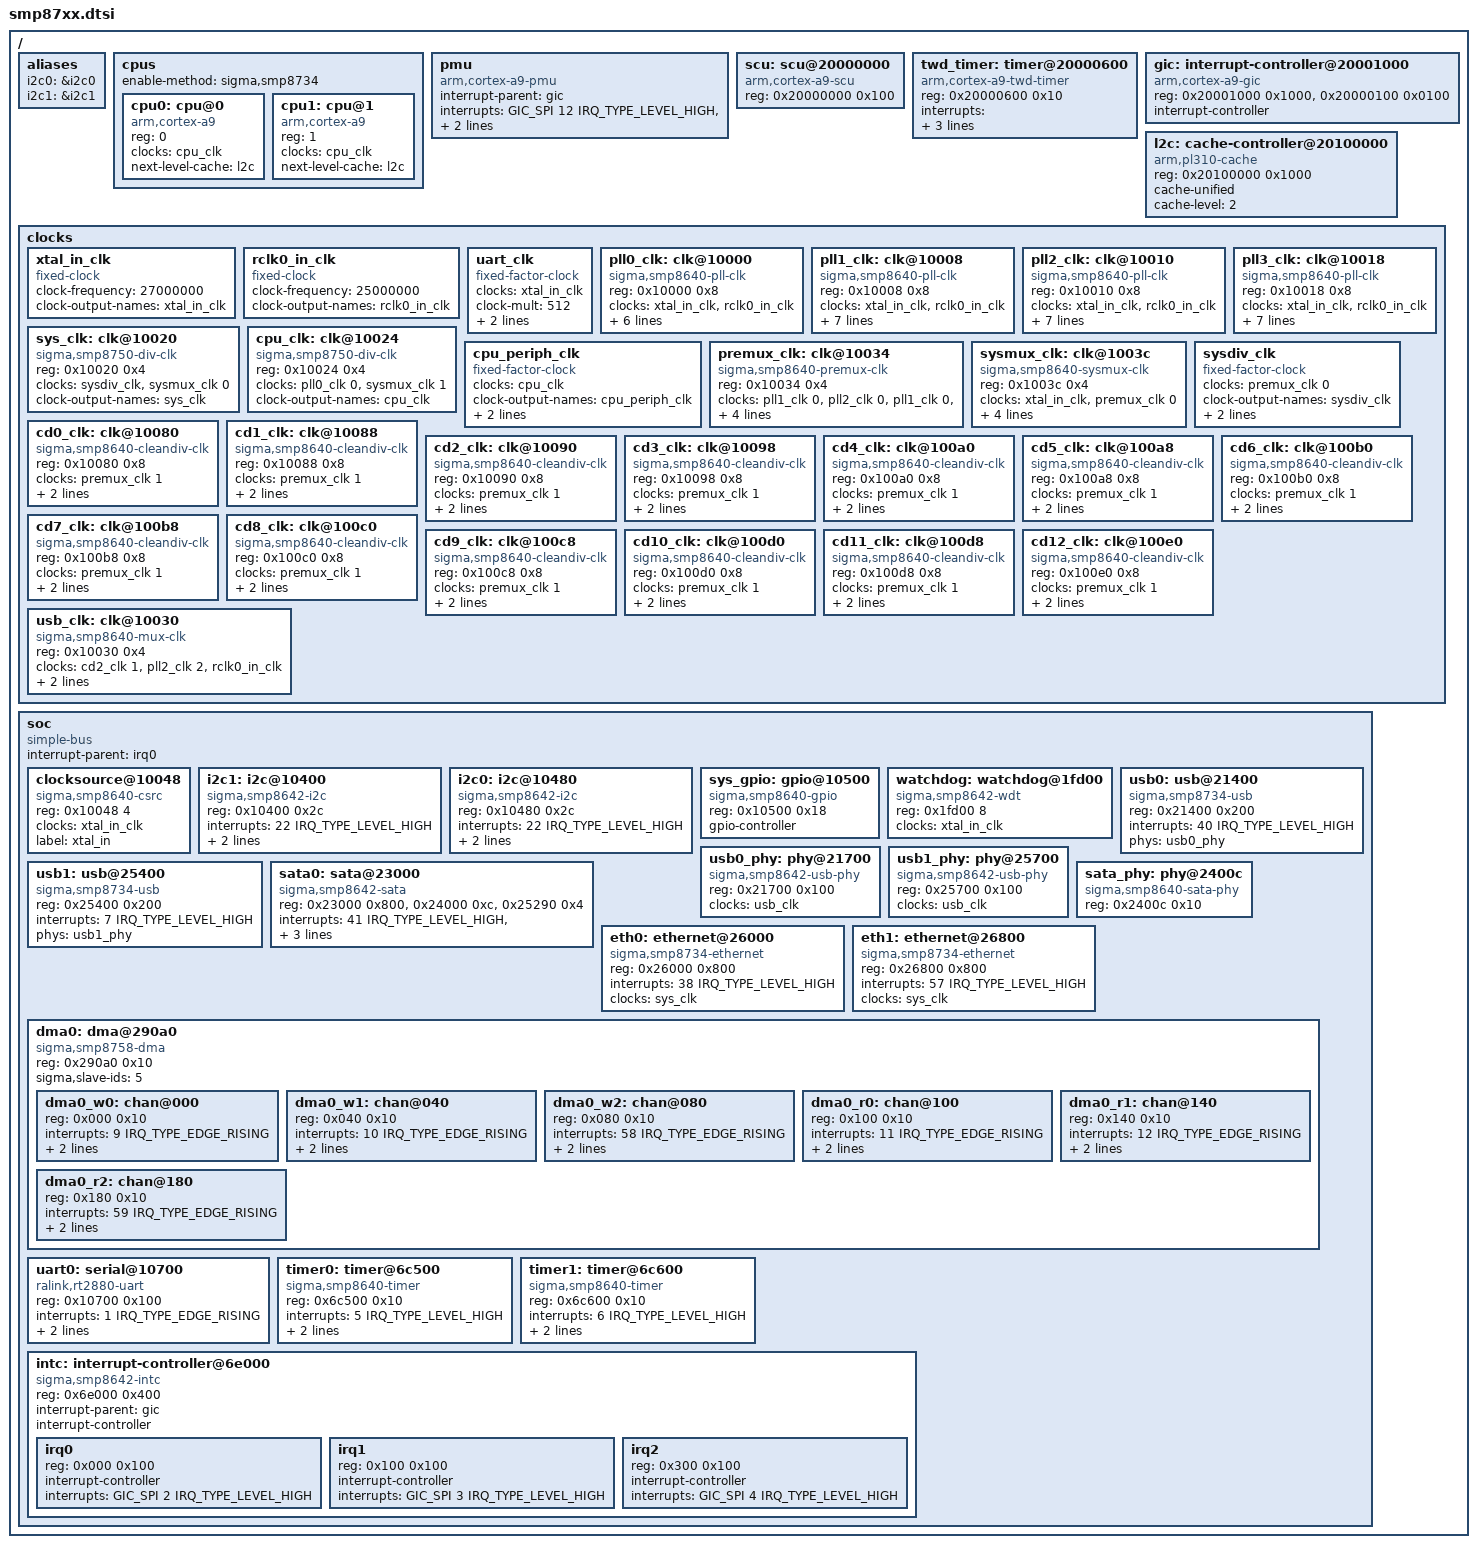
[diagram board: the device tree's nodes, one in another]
#include <dt-bindings/interrupt-controller/irq.h>
#include <dt-bindings/interrupt-controller/arm-gic.h>

/ {
	#address-cells = <1>;
	#size-cells = <1>;

	aliases {
		i2c0 = &i2c0;
		i2c1 = &i2c1;
	};

	cpus {
		enable-method = "sigma,smp8734";
		#address-cells = <1>;
		#size-cells = <0>;

		cpu0: cpu@0 {
			compatible = "arm,cortex-a9";
			device_type = "cpu";
			reg = <0>;
			clocks = <&cpu_clk>;
			next-level-cache = <&l2c>;
		};

		cpu1: cpu@1 {
			compatible = "arm,cortex-a9";
			device_type = "cpu";
			reg = <1>;
			clocks = <&cpu_clk>;
			next-level-cache = <&l2c>;
		};
	};

	pmu {
		compatible = "arm,cortex-a9-pmu";
		interrupt-parent = <&gic>;
		interrupts = <GIC_SPI 12 IRQ_TYPE_LEVEL_HIGH>,
			     <GIC_SPI 13 IRQ_TYPE_LEVEL_HIGH>;
		interrupt-affinity = <&cpu0>, <&cpu1>;
	};

	scu: scu@20000000 {
		compatible = "arm,cortex-a9-scu";
		reg = <0x20000000 0x100>;
	};

	twd_timer: timer@20000600 {
		compatible = "arm,cortex-a9-twd-timer";
		reg = <0x20000600 0x10>;
		interrupts = <GIC_PPI 13
			      (GIC_CPU_MASK_SIMPLE(4) | IRQ_TYPE_EDGE_RISING)>;
		interrupt-parent = <&gic>;
		clocks = <&cpu_periph_clk>;
	};

	gic: interrupt-controller@20001000 {
		compatible = "arm,cortex-a9-gic";
		reg = <0x20001000 0x1000>, <0x20000100 0x0100>;
		interrupt-controller;
		#interrupt-cells = <3>;
	};

	l2c: cache-controller@20100000 {
		compatible = "arm,pl310-cache";
		reg = <0x20100000 0x1000>;
		cache-unified;
		cache-level = <2>;
	};

	clocks {
		ranges;
		#address-cells = <1>;
		#size-cells = <1>;

		xtal_in_clk: xtal_in_clk {
			compatible = "fixed-clock";
			#clock-cells = <0>;
			clock-frequency = <27000000>;
			clock-output-names = "xtal_in_clk";
		};

		rclk0_in_clk: rclk0_in_clk {
			compatible = "fixed-clock";
			#clock-cells = <0>;
			clock-frequency = <25000000>;
			clock-output-names = "rclk0_in_clk";
		};

		uart_clk: uart_clk {
			compatible = "fixed-factor-clock";
			#clock-cells = <0>;
			clocks = <&xtal_in_clk>;
			clock-mult = <512>;
			clock-div = <1875>;
			clock-output-names = "uart_clk";
		};

		pll0_clk: clk@10000 {
			compatible = "sigma,smp8640-pll-clk";
			reg = <0x10000 0x8>;
			#clock-cells = <1>;
			clocks = <&xtal_in_clk>, <&rclk0_in_clk>;
			clock-output-names = "pll0_clk";
			sigma,mux-table = <1 4>;
			sigma,pll-n-bits = <7>;
			sigma,pll-m-bits = <7>;
			sigma,pll-k-bits = <3 13>;
			sigma,pll-mn-bias = <1>;
		};

		pll1_clk: clk@10008 {
			compatible = "sigma,smp8640-pll-clk";
			reg = <0x10008 0x8>;
			#clock-cells = <1>;
			clocks = <&xtal_in_clk>, <&rclk0_in_clk>;
			clock-output-names = "pll1_clk",
					     "pll1_d1_clk",
					     "pll1_d2_clk";
			sigma,mux-table = <1 4>;
			sigma,pll-n-bits = <7>;
			sigma,pll-m-bits = <7>;
			sigma,pll-k-bits = <3 13>;
			sigma,pll-mn-bias = <1>;
		};

		pll2_clk: clk@10010 {
			compatible = "sigma,smp8640-pll-clk";
			reg = <0x10010 0x8>;
			#clock-cells = <1>;
			clocks = <&xtal_in_clk>, <&rclk0_in_clk>;
			clock-output-names = "pll2_clk",
					     "pll2_d1_clk",
					     "pll2_d2_clk";
			sigma,mux-table = <1 4>;
			sigma,pll-n-bits = <7>;
			sigma,pll-m-bits = <7>;
			sigma,pll-k-bits = <3 13>;
			sigma,pll-mn-bias = <1>;
		};

		pll3_clk: clk@10018 {
			compatible = "sigma,smp8640-pll-clk";
			reg = <0x10018 0x8>;
			#clock-cells = <1>;
			clocks = <&xtal_in_clk>, <&rclk0_in_clk>;
			clock-output-names = "pll3_clk",
					     "pll3_d1_clk",
					     "pll3_d2_clk";
			sigma,mux-table = <1 4>;
			sigma,pll-n-bits = <7>;
			sigma,pll-m-bits = <3>;
			sigma,pll-k-bits = <3 13>;
			sigma,pll-mn-bias = <1>;
		};

		sys_clk: clk@10020 {
			compatible = "sigma,smp8750-div-clk";
			reg = <0x10020 0x4>;
			#clock-cells = <0>;
			clocks = <&sysdiv_clk>, <&sysmux_clk 0>;
			clock-output-names = "sys_clk";
		};

		cpu_clk: clk@10024 {
			compatible = "sigma,smp8750-div-clk";
			reg = <0x10024 0x4>;
			#clock-cells = <0>;
			clocks = <&pll0_clk 0>, <&sysmux_clk 1>;
			clock-output-names = "cpu_clk";
		};

		cpu_periph_clk: cpu_periph_clk {
			compatible = "fixed-factor-clock";
			#clock-cells = <0>;
			clocks = <&cpu_clk>;
			clock-output-names = "cpu_periph_clk";
			clock-mult = <1>;
			clock-div = <2>;
		};

		premux_clk: clk@10034 {
			compatible = "sigma,smp8640-premux-clk";
			reg = <0x10034 0x4>;
			#clock-cells = <1>;
			clocks = <&pll1_clk 0>, <&pll2_clk 0>,
				 <&pll1_clk 0>, <&pll1_clk 1>,
				 <&pll2_clk 0>, <&pll2_clk 1>;
			clock-output-names = "pll_sys_clk", "cd_clk";
			sigma,sys-table = <1 2>;
			sigma,cd-table = <2 3 4 5>;
		};

		sysmux_clk: clk@1003c {
			compatible = "sigma,smp8640-sysmux-clk";
			reg = <0x1003c 0x4>;
			#clock-cells = <1>;
			clocks = <&xtal_in_clk>, <&premux_clk 0>;
			clock-output-names = "sys_bp_clk", "cpu_bp_clk",
					     "dsp_clk";
			sigma,divisors = <2 4 3 3 3 3 3 3 4 4 4 4
					  2 2 2 3 3 2 3 2 4 2 4 2
					  2 4 3 3 3 3 3 3 4 4 4 4>;
		};

		sysdiv_clk: sysdiv_clk {
			compatible = "fixed-factor-clock";
			#clock-cells = <0>;
			clocks = <&premux_clk 0>;
			clock-output-names = "sysdiv_clk";
			clock-mult = <1>;
			clock-div = <4>;
		};

		cd0_clk: clk@10080 {
			compatible = "sigma,smp8640-cleandiv-clk";
			reg = <0x10080 0x8>;
			#clock-cells = <1>;
			clocks = <&premux_clk 1>;
			clock-output-names = "cd0_clk",
					     "cd0_2_clk",
					     "cd0_4_clk";
		};

		cd1_clk: clk@10088 {
			compatible = "sigma,smp8640-cleandiv-clk";
			reg = <0x10088 0x8>;
			#clock-cells = <1>;
			clocks = <&premux_clk 1>;
			clock-output-names = "cd1_clk",
					     "cd1_2_clk",
					     "cd1_4_clk";
		};

		cd2_clk: clk@10090 {
			compatible = "sigma,smp8640-cleandiv-clk";
			reg = <0x10090 0x8>;
			#clock-cells = <1>;
			clocks = <&premux_clk 1>;
			clock-output-names = "cd2_clk",
					     "cd2_2_clk",
					     "cd2_4_clk";
		};

		cd3_clk: clk@10098 {
			compatible = "sigma,smp8640-cleandiv-clk";
			reg = <0x10098 0x8>;
			#clock-cells = <1>;
			clocks = <&premux_clk 1>;
			clock-output-names = "cd3_clk",
					     "cd3_2_clk",
					     "cd3_4_clk";
		};

		cd4_clk: clk@100a0 {
			compatible = "sigma,smp8640-cleandiv-clk";
			reg = <0x100a0 0x8>;
			#clock-cells = <1>;
			clocks = <&premux_clk 1>;
			clock-output-names = "cd4_clk",
					     "cd4_2_clk",
					     "cd4_4_clk";
		};

		cd5_clk: clk@100a8 {
			compatible = "sigma,smp8640-cleandiv-clk";
			reg = <0x100a8 0x8>;
			#clock-cells = <1>;
			clocks = <&premux_clk 1>;
			clock-output-names = "cd5_clk",
					     "cd5_2_clk",
					     "cd5_4_clk";
		};

		cd6_clk: clk@100b0 {
			compatible = "sigma,smp8640-cleandiv-clk";
			reg = <0x100b0 0x8>;
			#clock-cells = <1>;
			clocks = <&premux_clk 1>;
			clock-output-names = "cd6_clk",
					     "cd6_2_clk",
					     "cd6_4_clk";
		};

		cd7_clk: clk@100b8 {
			compatible = "sigma,smp8640-cleandiv-clk";
			reg = <0x100b8 0x8>;
			#clock-cells = <1>;
			clocks = <&premux_clk 1>;
			clock-output-names = "cd7_clk",
					     "cd7_2_clk",
					     "cd7_4_clk";
		};

		cd8_clk: clk@100c0 {
			compatible = "sigma,smp8640-cleandiv-clk";
			reg = <0x100c0 0x8>;
			#clock-cells = <1>;
			clocks = <&premux_clk 1>;
			clock-output-names = "cd8_clk",
					     "cd8_2_clk",
					     "cd8_4_clk";
		};

		cd9_clk: clk@100c8 {
			compatible = "sigma,smp8640-cleandiv-clk";
			reg = <0x100c8 0x8>;
			#clock-cells = <1>;
			clocks = <&premux_clk 1>;
			clock-output-names = "cd9_clk",
					     "cd9_2_clk",
					     "cd9_4_clk";
		};

		cd10_clk: clk@100d0 {
			compatible = "sigma,smp8640-cleandiv-clk";
			reg = <0x100d0 0x8>;
			#clock-cells = <1>;
			clocks = <&premux_clk 1>;
			clock-output-names = "cd10_clk",
					     "cd10_2_clk",
					     "cd10_4_clk";
		};

		cd11_clk: clk@100d8 {
			compatible = "sigma,smp8640-cleandiv-clk";
			reg = <0x100d8 0x8>;
			#clock-cells = <1>;
			clocks = <&premux_clk 1>;
			clock-output-names = "cd11_clk",
					     "cd11_2_clk",
					     "cd11_4_clk";
		};

		cd12_clk: clk@100e0 {
			compatible = "sigma,smp8640-cleandiv-clk";
			reg = <0x100e0 0x8>;
			#clock-cells = <1>;
			clocks = <&premux_clk 1>;
			clock-output-names = "cd12_clk",
					     "cd12_2_clk",
					     "cd12_4_clk";
		};

		usb_clk: clk@10030 {
			compatible = "sigma,smp8640-mux-clk";
			reg = <0x10030 0x4>;
			#clock-cells = <0>;
			clocks = <&cd2_clk 1>, <&pll2_clk 2>, <&rclk0_in_clk>;
			clock-output-names = "usb_clk";
			sigma,bits = <8 4>;
		};
	};

	soc {
		compatible = "simple-bus";
		interrupt-parent = <&irq0>;
		#address-cells = <1>;
		#size-cells = <1>;
		ranges;

		clocksource@10048 {
			compatible = "sigma,smp8640-csrc";
			reg = <0x10048 4>;
			clocks = <&xtal_in_clk>;
			label = "xtal_in";
		};

		i2c1: i2c@10400 {
			compatible = "sigma,smp8642-i2c";
			reg = <0x10400 0x2c>;
			interrupts = <22 IRQ_TYPE_LEVEL_HIGH>;
			clocks = <&sys_clk>;
			clock-frequency = <100000>;
			#address-cells = <1>;
			#size-cells = <0>;
		};

		i2c0: i2c@10480 {
			compatible = "sigma,smp8642-i2c";
			reg = <0x10480 0x2c>;
			interrupts = <22 IRQ_TYPE_LEVEL_HIGH>;
			clocks = <&sys_clk>;
			clock-frequency = <100000>;
			#address-cells = <1>;
			#size-cells = <0>;
		};

		sys_gpio: gpio@10500 {
			compatible = "sigma,smp8640-gpio";
			reg = <0x10500 0x18>;
			gpio-controller;
			#gpio-cells = <2>;
		};

		watchdog: watchdog@1fd00 {
			compatible = "sigma,smp8642-wdt";
			reg = <0x1fd00 8>;
			clocks = <&xtal_in_clk>;
		};

		usb0: usb@21400 {
			compatible = "sigma,smp8734-usb", "chipidea,usb2";
			reg = <0x21400 0x200>;
			interrupts = <40 IRQ_TYPE_LEVEL_HIGH>;
			phys = <&usb0_phy>;
			phy-names = "usb-phy";
		};

		usb0_phy: phy@21700 {
			compatible = "sigma,smp8642-usb-phy";
			reg = <0x21700 0x100>;
			#phy-cells = <0>;
			clocks = <&usb_clk>;
		};

		usb1: usb@25400 {
			compatible = "sigma,smp8734-usb", "chipidea,usb2";
			reg = <0x25400 0x200>;
			interrupts = <7 IRQ_TYPE_LEVEL_HIGH>;
			phys = <&usb1_phy>;
			phy-names = "usb-phy";
		};

		usb1_phy: phy@25700 {
			compatible = "sigma,smp8642-usb-phy";
			reg = <0x25700 0x100>;
			#phy-cells = <0>;
			clocks = <&usb_clk>;
		};

		sata0: sata@23000 {
			compatible = "sigma,smp8642-sata";
			reg = <0x23000 0x800>,
			      <0x24000 0xc>,
			      <0x25290 0x4>;
			interrupts = <41 IRQ_TYPE_LEVEL_HIGH>,
				     <42 IRQ_TYPE_LEVEL_HIGH>;
			dmas = <&dma0 5>;
			dma-names = "sata-dma";
			phys = <&sata_phy>;
			phy-names = "sata-phy";
		};

		sata_phy: phy@2400c {
			compatible = "sigma,smp8640-sata-phy";
			reg = <0x2400c 0x10>;
			#phy-cells = <0>;
		};

		eth0: ethernet@26000 {
			compatible = "sigma,smp8734-ethernet";
			reg = <0x26000 0x800>;
			interrupts = <38 IRQ_TYPE_LEVEL_HIGH>;
			clocks = <&sys_clk>;
			#address-cells = <1>;
			#size-cells = <0>;
		};

		eth1: ethernet@26800 {
			compatible = "sigma,smp8734-ethernet";
			reg = <0x26800 0x800>;
			interrupts = <57 IRQ_TYPE_LEVEL_HIGH>;
			clocks = <&sys_clk>;
			#address-cells = <1>;
			#size-cells = <0>;
		};

		dma0: dma@290a0 {
			compatible = "sigma,smp8758-dma";
			reg = <0x290a0 0x10>;
			ranges = <0x0 0x2b000 0x200>;
			#dma-cells = <1>;
			sigma,slave-ids = <5>;
			#address-cells = <1>;
			#size-cells = <1>;

			dma0_w0: chan@000 {
				reg = <0x000 0x10>;
				interrupts = <9 IRQ_TYPE_EDGE_RISING>;
				sigma,sbox-id = <1>;
				sigma,dev-to-mem;
			};

			dma0_w1: chan@040 {
				reg = <0x040 0x10>;
				interrupts = <10 IRQ_TYPE_EDGE_RISING>;
				sigma,sbox-id = <2>;
				sigma,dev-to-mem;
			};

			dma0_w2: chan@080 {
				reg = <0x080 0x10>;
				interrupts = <58 IRQ_TYPE_EDGE_RISING>;
				sigma,sbox-id = <9>;
				sigma,dev-to-mem;
			};

			dma0_r0: chan@100 {
				reg = <0x100 0x10>;
				interrupts = <11 IRQ_TYPE_EDGE_RISING>;
				sigma,sbox-id = <1>;
				sigma,mem-to-dev;
			};

			dma0_r1: chan@140 {
				reg = <0x140 0x10>;
				interrupts = <12 IRQ_TYPE_EDGE_RISING>;
				sigma,sbox-id = <2>;
				sigma,mem-to-dev;
			};

			dma0_r2: chan@180 {
				reg = <0x180 0x10>;
				interrupts = <59 IRQ_TYPE_EDGE_RISING>;
				sigma,sbox-id = <9>;
				sigma,mem-to-dev;
			};
		};

		uart0: serial@10700 {
			compatible = "ralink,rt2880-uart";
			reg = <0x10700 0x100>;
			interrupts = <1 IRQ_TYPE_EDGE_RISING>;
			clocks = <&uart_clk>;
			reg-shift = <2>;
		};

		timer0: timer@6c500 {
			compatible = "sigma,smp8640-timer";
			reg = <0x6c500 0x10>;
			interrupts = <5 IRQ_TYPE_LEVEL_HIGH>;
			clocks = <&sys_clk>;
			label = "tangox_timer0";
		};

		timer1: timer@6c600 {
			compatible = "sigma,smp8640-timer";
			reg = <0x6c600 0x10>;
			interrupts = <6 IRQ_TYPE_LEVEL_HIGH>;
			clocks = <&xtal_in_clk>;
			label = "tangox_timer1";
		};

		intc: interrupt-controller@6e000 {
			compatible = "sigma,smp8642-intc";
			reg = <0x6e000 0x400>;
			ranges = <0x0 0x6e000 0x400>;
			interrupt-parent = <&gic>;
			interrupt-controller;
			#address-cells = <1>;
			#size-cells = <1>;

			irq0: irq0 {
				reg = <0x000 0x100>;
				interrupt-controller;
				#interrupt-cells = <2>;
				interrupts = <GIC_SPI 2 IRQ_TYPE_LEVEL_HIGH>;
			};

			irq1: irq1 {
				reg = <0x100 0x100>;
				interrupt-controller;
				#interrupt-cells = <2>;
				interrupts = <GIC_SPI 3 IRQ_TYPE_LEVEL_HIGH>;
			};

			irq2: irq2 {
				reg = <0x300 0x100>;
				interrupt-controller;
				#interrupt-cells = <2>;
				interrupts = <GIC_SPI 4 IRQ_TYPE_LEVEL_HIGH>;
			};
		};
	};
};
